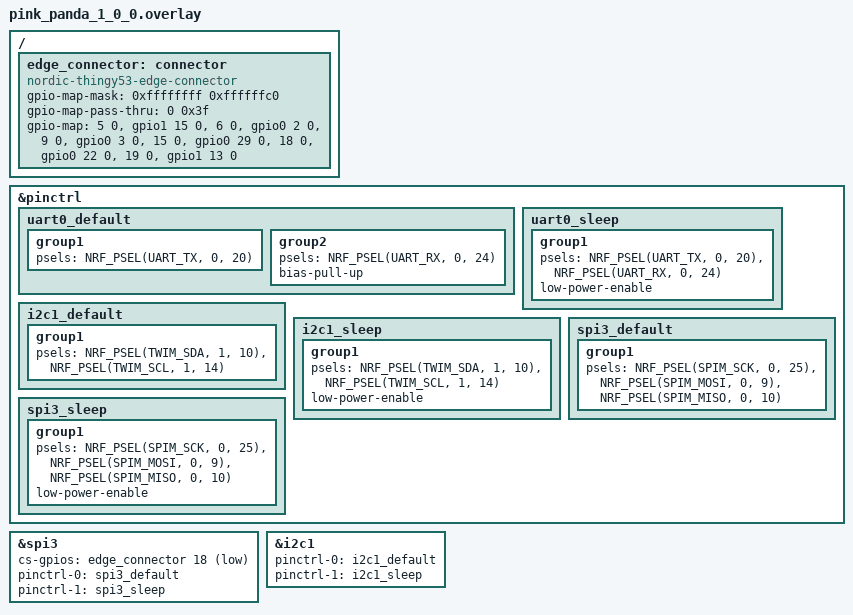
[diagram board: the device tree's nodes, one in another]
/ {
	edge_connector: connector {
		compatible = "nordic-thingy53-edge-connector";
		#gpio-cells = <2>;
		gpio-map-mask = <0xffffffff 0xffffffc0>;
		gpio-map-pass-thru = <0 0x3f>;
		gpio-map = <5 0 &gpio1 15 0>,	/* P5, Coex ST0 */
			   <6 0 &gpio0 2 0>,	/* P6, Coex REQ */
			   <9 0 &gpio0 3 0>,	/* P9, EN */
			   <15 0 &gpio0 29 0>,	/* P15, Coex GRT */
			   <18 0 &gpio0 22 0>,	/* P18, CS */
			   <19 0 &gpio1 13 0>;	/* P19, IRQ */
	};
};
&pinctrl {
	uart0_default: uart0_default {
		group1 {
			psels = <NRF_PSEL(UART_TX, 0, 20)>;
		};
		group2 {
			psels = <NRF_PSEL(UART_RX, 0, 24)>;
			bias-pull-up;
		};
	};

	uart0_sleep: uart0_sleep {
		group1 {
			psels = <NRF_PSEL(UART_TX, 0, 20)>,
				<NRF_PSEL(UART_RX, 0, 24)>;
			low-power-enable;
		};
	};

	i2c1_default: i2c1_default {
		group1 {
			psels = <NRF_PSEL(TWIM_SDA, 1, 10)>,
				<NRF_PSEL(TWIM_SCL, 1, 14)>;
		};
	};

	i2c1_sleep: i2c1_sleep {
		group1 {
			psels = <NRF_PSEL(TWIM_SDA, 1, 10)>,
				<NRF_PSEL(TWIM_SCL, 1, 14)>;
			low-power-enable;
		};
	};

	spi3_default: spi3_default {
		group1 {
			psels = <NRF_PSEL(SPIM_SCK, 0, 25)>,
				<NRF_PSEL(SPIM_MOSI, 0, 9)>,
				<NRF_PSEL(SPIM_MISO, 0, 10)>;
		};
	};

	spi3_sleep: spi3_sleep {
		group1 {
			psels = <NRF_PSEL(SPIM_SCK, 0, 25)>,
				<NRF_PSEL(SPIM_MOSI, 0, 9)>,
				<NRF_PSEL(SPIM_MISO, 0, 10)>;
			low-power-enable;
		};
	};
};
edge_connector_spi: &spi3 {
	cs-gpios = <&edge_connector 18 GPIO_ACTIVE_LOW>;
	pinctrl-0 = <&spi3_default>;
	pinctrl-1 = <&spi3_sleep>;
	pinctrl-names = "default", "sleep";
};
zephyr_i2c: &i2c1 {
	pinctrl-0 = <&i2c1_default>;
	pinctrl-1 = <&i2c1_sleep>;
	pinctrl-names = "default", "sleep";
};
